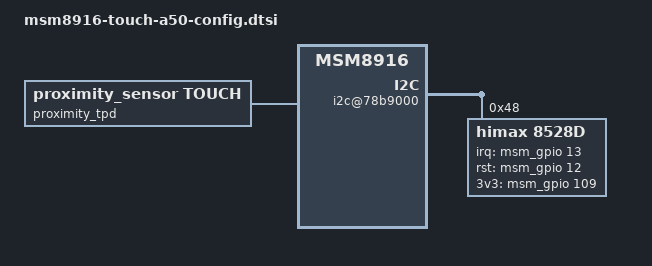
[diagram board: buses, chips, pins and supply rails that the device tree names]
/* Copyright (c) 2013, The Linux Foundation. All rights reserved.
 *
 * This program is free software; you can redistribute it and/or modify
 * it under the terms of the GNU General Public License version 2 and
 * only version 2 as published by the Free Software Foundation.
 *
 * This program is distributed in the hope that it will be useful,
 * but WITHOUT ANY WARRANTY; without even the implied warranty of
 * MERCHANTABILITY or FITNESS FOR A PARTICULAR PURPOSE.  See the
 * GNU General Public License for more details.
 */

&soc {
	proximity_tpd {
		compatible = "proximity_sensor,touch";
	};

	i2c@78b9000 { /* BLSP1 QUP5 */
		himax@48 {
			compatible               	= "himax,8528d";
			reg                      		= <0x48>;
			interrupt-parent         	= <&msm_gpio>;
			interrupts               	= <13 0x2>;
			himax,panel-coords   	= <0 1080 0 1920>;
			himax,display-coords 	= <0 720 0 1280>;
			himax,irq-gpio       	= <&msm_gpio 13 0x00>;
			himax,rst-gpio       	= <&msm_gpio 12 0x00>;
			himax,3v3-gpio       	= <&msm_gpio 109 0x00>;
			report_type              	= <1>;

			config0 {	//YO
				fw_ver     	= <0xC1>;
				sensor_id     	= <0x22>;
				c1 =[37 FF 08 FF 08];
				c2 =[3F 00];
				c3 =[62 01 00 21 00 00 00 00 00 22 22];
				c4 =[63 01 00 31 02 00 00 00 00 22 22];
				c5 =[64 01 00 21 03 00 00 00 00 22 22];
				c6 =[65 01 00 31 02 00 00 00 00 22 22];
				c7 =[66 01 00 21 03 00 00 00 00 22 22];
				c8 =[67 01 00 31 02 00 00 00 00 22 22];
				c9 =[68 01 00 21 03 00 00 00 00 22 22];
				c10 =[69 01 00 31 02 00 00 00 00 22 22];
				c11 =[6A 01 00 21 03 00 00 00 00 22 22];
				c12 =[6B 01 00 31 02 00 00 00 00 22 22];
				c13 =[6C 01 00 21 03 00 00 00 00 00 00];
				c14 =[6D 01 00 01 02 00 00 00 00 00 00];
				c15 =[6E 01 00 21 00 00 00 00 00 00 00];
				c16 =[6F 01 00 01 02 00 00 00 00 00 00];
				c17 =[70 01 00 31 00 00 00 00 00 00 00];
				c18 =[7B 03];
				c19 =[7C 00 D8 0C];
				c20 =[7F 00 04 0A 0A 04 00 00 00];
				c21 =[A4 94 62 94 86];
				c22 =[B4 07 01 02 02 02 02 0F 02 07 02
				          07 02 07 08];
				c23 =[B9 01 36];
				c24 =[BA 00];
				c25 =[BB 00];
				c26 =[BC 00 00 00 00];
				c27 =[BD 04 0C];
				c28 =[C2 10 00 00 00 00 00 00 00];
				c29 =[C5 0A 1B 00 10 19 1E 0B 1B 08 16];
				c30 =[C6 17 10 1C];
				c31 =[C9 00 00 00 2D 28 26 24 22 20 1C
				          1A 18 16 14 12 10 29 27 25 23
				          21 1D 1B 19 17 15 13 11 00 00
				          00 00 00 00 00 00 00 00 00 00
				          00 00 00 00 00 00 00 00 00 00
				          00 00 00 00 00 00 00 00 00 00
				          00 00 00 00];
				c32 =[CB 01 F5 FF FF 01 00 05 00 5F 00
				          00 00];
				c33 =[D0 06 01];
				c34 =[D3 06 01];
				c35 =[D5 29 00 00 00 00 00 00 00 00 00
				          00 00 00 00 00 00];
				c36 =[40 01 5A
				          5F 00 F0 10 00 00
				          1C 0C 0B 0F 09 09 09 0B 0B 0B
				          24 20 40 40 3C 00 00 00 00 00
				          00 00];
				c37 =[40 94 0A F0 83 84 00
				          48 24 0F 0F 83 3C 00 00
				          11 00 41 42
				          0F 2F 00 12 00 00
				          10 02 3C 64 00 00];
				c38 =[40 18 2F 2F 02 19 00 00 00
				          04 06 24 07 07 00 00 00];
				c39 =[40 30 28 05 02 00 D8 0C 00 00 02
				          03 80 00 00 00 00
				          10 02 80 00 00 00 00 0C];
				c40 =[40 00 00 00 00 00 00 00 00
				          A0 82 2D 00
				          0F 19 A0 13
				          00 00 04 38 07 80];
				c41 =[40 02 60 06 3B 53 33 08 00 7A 02
				          23 53 67 0A
				          03 5F 08 D8 57 64 00 00 B9 03
				          40 56 75 00];
				c42 =[40 00 00 00 00 00 00 00 00];
				c43_1 =[40 03 27 FF FF 04 26 19 FF 05 25
				             18 FF 06 24 17 FF 07 23 16 FF
				             02 22 15 FF 01 21 14 FF 00 20
				             13];
				c43_2 =[40 FF 08 1F 12 FF 09 1E 11 FF
				             0A 1D 10 FF 0B 1C FF FF 0C 1B
				             FF FF 0D 1A FF FF 0E FF 0F FF];
				c44_1 =[40 A3 00 20 00 13 1E 32 00 00 00
				             00 00 00 00 00 00 00 00 00 00
				             00 00 00 00 00 00 00 00 00 00
				             56];
				c44_2 =[40 02 12 02 00 04];
				c45   =[40 00 00];
			};
			config1 {	//Om
				fw_ver     	= <0xC1>;
				sensor_id     	= <0x21>;
				c1 =[37 FF 08 FF 08];
				c2 =[3F 00];
				c3 =[62 01 00 21 00 00 00 00 00 22 12];
				c4 =[63 01 00 31 02 00 00 00 00 11 11];
				c5 =[64 01 00 21 03 00 00 00 00 11 11];
				c6 =[65 01 00 31 02 00 00 00 00 11 31];
				c7 =[66 01 00 21 03 00 00 00 00 33 33];
				c8 =[67 01 00 31 02 00 00 00 00 33 33];
				c9 =[68 01 00 21 03 00 00 00 00 33 33];
				c10 =[69 01 00 31 02 00 00 00 00 33 33];
				c11 =[6A 01 00 21 03 00 00 00 00 33 33];
				c12 =[6B 01 00 31 02 00 00 00 00 33 23];
				c13 =[6C 01 00 21 03 00 00 00 00 00 00];
				c14 =[6D 01 00 01 02 00 00 00 00 00 00];
				c15 =[6E 01 00 21 00 00 00 00 00 00 00];
				c16 =[6F 01 00 01 02 00 00 00 00 00 00];
				c17 =[70 01 00 31 00 00 00 00 00 00 00];
				c18 =[7B 03];
				c19 =[7C 00 D8 0C];
				c20 =[7F 00 04 0A 0A 04 00 00 00];
				c21 =[A4 94 62 94 86];
				c22 =[B4 05 01 02 02 02 03 0F 04 07 04
				          07 04 07 08];
				c23 =[B9 01 56];
				c24 =[BA 00];
				c25 =[BB 00];
				c26 =[BC 00 00 00 00];
				c27 =[BD 04 0C];
				c28 =[C2 10 00 00 00 00 00 00 00];
				c29 =[C5 0B 1B 00 10 1A 1E 0B 1A 08 16];
				c30 =[C6 15 10 1A];
				c31 =[C9 00 00 00 2D 28 26 24 22 20 1C
				          1A 18 16 14 12 10 29 27 25 23
				          21 1D 1B 19 17 15 13 11 00 00
				          00 00 00 00 00 00 00 00 00 00
				          00 00 00 00 00 00 00 00 00 00
				          00 00 00 00 00 00 00 00 00 00
				          00 00 00 00];
				c32 =[CB 01 F5 FF FF 01 00 05 00 7F 00
				          00 00];
				c33 =[D0 06 01];
				c34 =[D3 06 01];
				c35 =[D5 29 00 00 00 00 00 00 00 00 00
				          00 00 00 00 00 00];
				c36 =[40 09 5A
				          5F 00 F0 10 00 00
				          1C 0C 0B 0F 09 09 09 08 08 08
				          24 20 40 40 3C 00 00 00 00 00
				          00 00];
				c37 =[40 94 0A F0 83 84 00
				          48 24 0F 0F 83 3C 00 00
				          11 00 41 42
				          0F 28 00 12 00 00
				          10 02 3C 64 00 00];
				c38 =[40 18 3F 3F 02 19 00 00 00
				          04 06 24 05 05 00 00 00];
				c39 =[40 30 1F 05 02 00 D8 0C 00 00 02
				          03 80 00 00 00 00
				          10 02 80 00 00 00 00 0C];
				c40 =[40 00 00 00 00 00 00 00 00
				          A0 82 2D 00
				          0F 19 A0 13
				          00 00 04 38 07 80];
				c41 =[40 02 60 06 3B 53 33 08 00 7A 02
				          23 53 67 0A
				          03 5F 08 D8 57 64 00 00 B9 03
				          40 56 75 00];
				c42 =[40 00 00 00 00 00 00 00 00];
				c43_1 =[40 03 27 FF FF 04 26 19 FF 05 25
				             18 FF 06 24 17 FF 07 23 16 FF
				             02 22 15 FF 01 21 14 FF 00 20
				             13];
				c43_2 =[40 FF 08 1F 12 FF 09 1E 11 FF
				             0A 1D 10 FF 0B 1C FF FF 0C 1B
				             FF FF 0D 1A FF FF 0E FF 0F FF];
				c44_1 =[40 A3 00 20 00 13 1E 32 00 00 00
				             00 00 00 00 00 00 00 00 00 00
				             00 00 00 00 00 00 00 00 00 00
				             56];
				c44_2 =[40 02 12 02 00 04];
				c45   =[40 00 00];
			};
			config2 {	//YO
				default_cfg   	= <1>;
				fw_ver     	= <0x04>;
				c1 =[37 FF 08 FF 08];
				c2 =[3F 00];
				c3 =[62 01 00 21 00 00 00 00 00 22 22];
				c4 =[63 01 00 31 02 00 00 00 00 22 22];
				c5 =[64 01 00 21 03 00 00 00 00 22 22];
				c6 =[65 01 00 31 02 00 00 00 00 22 22];
				c7 =[66 01 00 21 03 00 00 00 00 22 22];
				c8 =[67 01 00 31 02 00 00 00 00 22 22];
				c9 =[68 01 00 21 03 00 00 00 00 22 22];
				c10 =[69 01 00 31 02 00 00 00 00 22 22];
				c11 =[6A 01 00 21 03 00 00 00 00 22 22];
				c12 =[6B 01 00 31 02 00 00 00 00 22 22];
				c13 =[6C 01 00 21 03 00 00 00 00 00 00];
				c14 =[6D 01 00 01 02 00 00 00 00 00 00];
				c15 =[6E 01 00 21 00 00 00 00 00 00 00];
				c16 =[6F 01 00 01 02 00 00 00 00 00 00];
				c17 =[70 01 00 31 00 00 00 00 00 00 00];
				c18 =[7B 03];
				c19 =[7C 00 D8 0C];
				c20 =[7F 00 04 0A 0A 04 00 00 00];
				c21 =[A4 94 62 94 86];
				c22 =[B4 07 01 02 02 02 02 0F 02 07 02
				          07 02 07 08];
				c23 =[B9 01 36];
				c24 =[BA 00];
				c25 =[BB 00];
				c26 =[BC 00 00 00 00];
				c27 =[BD 04 0C];
				c28 =[C2 10 00 00 00 00 00 00 00];
				c29 =[C5 0A 1B 00 10 19 1E 0B 1B 08 16];
				c30 =[C6 17 10 1C];
				c31 =[C9 00 00 00 2D 28 26 24 22 20 1C
				          1A 18 16 14 12 10 29 27 25 23
				          21 1D 1B 19 17 15 13 11 00 00
				          00 00 00 00 00 00 00 00 00 00
				          00 00 00 00 00 00 00 00 00 00
				          00 00 00 00 00 00 00 00 00 00
				          00 00 00 00];
				c32 =[CB 01 F5 FF FF 01 00 05 00 5F 00
				          00 00];
				c33 =[D0 06 01];
				c34 =[D3 06 01];
				c35 =[D5 29 00 00 00 00 00 00 00 00 00
				          00 00 00 00 00 00];
				c36 =[40 01 5A
				          5F 00 F0 10 00 00
				          1C 0C 0B 0F 09 09 09 0B 0B 0B
				          24 20 40 40 3C 00 00 00 00 00
				          00 00];
				c37 =[40 94 0A F0 83 84 00
				          48 24 0F 0F 83 3C 00 00
				          11 00 41 42
				          0F 2F 00 12 00 00
				          10 02 3C 64 00 00];
				c38 =[40 18 2F 2F 02 19 00 00 00
				          04 06 24 07 07 00 00 00];
				c39 =[40 30 28 05 02 00 D8 0C 00 00 02
				          03 80 00 00 00 00
				          10 02 80 00 00 00 00 0C];
				c40 =[40 00 00 00 00 00 00 00 00
				          A0 82 2D 00
				          0F 19 A0 13
				          00 00 04 38 07 80];
				c41 =[40 02 60 06 3B 53 33 08 00 7A 02
				          23 53 67 0A
				          03 5F 08 D8 57 64 00 00 B9 03
				          40 56 75 00];
				c42 =[40 00 00 00 00 00 00 00 00];
				c43_1 =[40 03 27 FF FF 04 26 19 FF 05 25
				             18 FF 06 24 17 FF 07 23 16 FF
				             02 22 15 FF 01 21 14 FF 00 20
				             13];
				c43_2 =[40 FF 08 1F 12 FF 09 1E 11 FF
				             0A 1D 10 FF 0B 1C FF FF 0C 1B
				             FF FF 0D 1A FF FF 0E FF 0F FF];
				c44_1 =[40 A3 00 20 00 13 1E 32 00 00 00
				             00 00 00 00 00 00 00 00 00 00
				             00 00 00 00 00 00 00 00 00 00
				             56];
				c44_2 =[40 02 12 02 00 04];
				c45   =[40 00 00];
			};
		};
	};
};
